AUTOSAR XML (schema 4-0-3)
standard types defined: Boolean, uint8, UInt16, UInt32, UInt8
package /AUTOSAR_Platform/DataConstrs
  range DC_Boolean: raw 0..1
  range DC_UInt16: raw 0..65535
  range DC_UInt8: raw 0..255
package /PATAC/Facility/DataTypes/Implementation
  compu method COMPU_Boolean: 0=FALSE, 1=TRUE
  unit NoUnit: factor-si-to-unit=1, offset-si-to-unit=0
package /PATAC/MSM/ComponentTypes
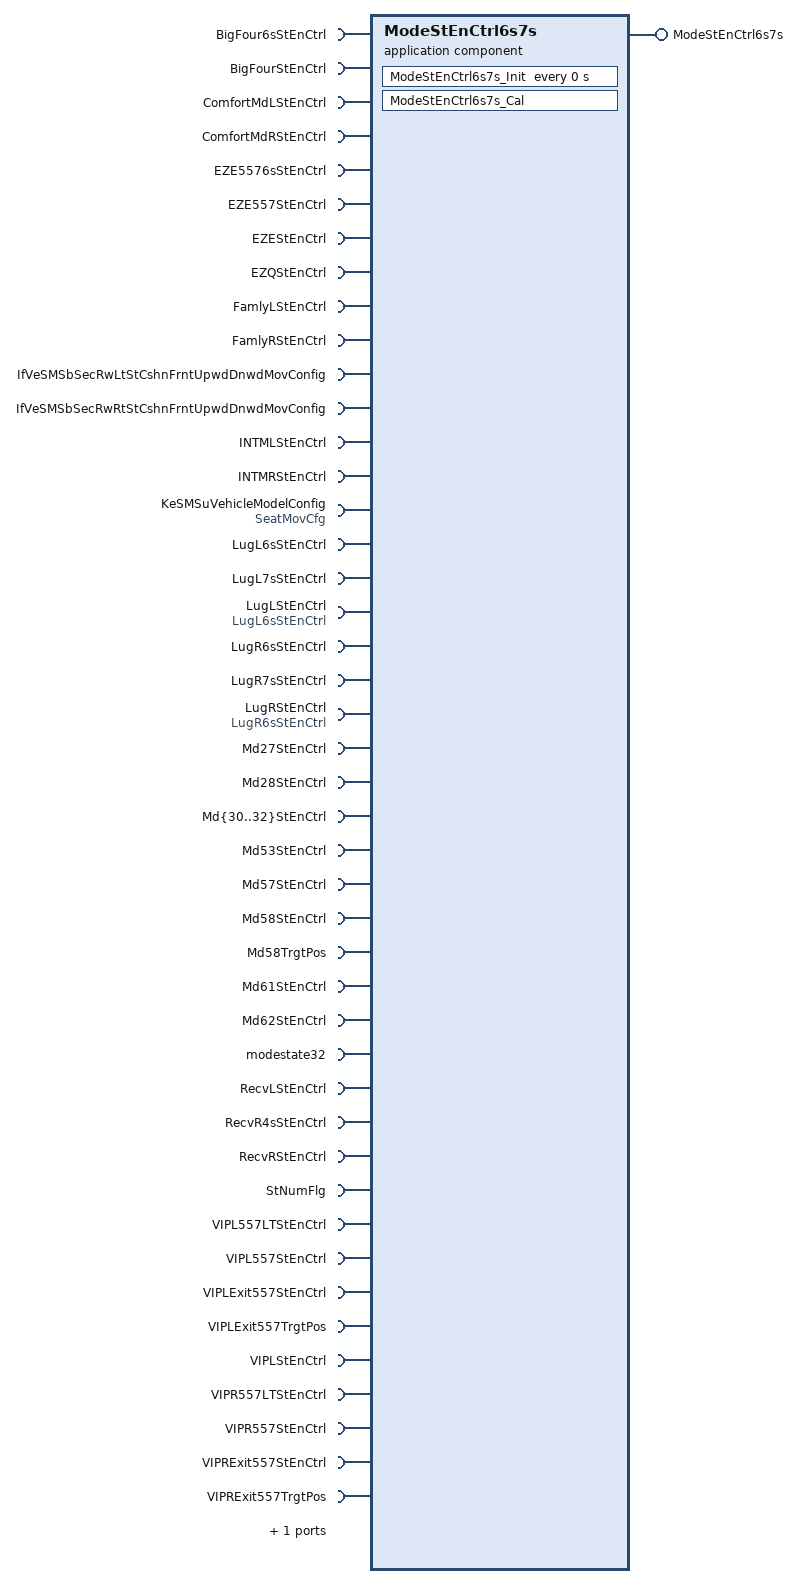
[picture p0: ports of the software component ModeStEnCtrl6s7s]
  application sw component type ModeStEnCtrl6s7s
    provide port ModeStEnCtrl6s7s: server-com-spec{operation=ModeStEnCtrl6s7s/Cal, queue-length=1}, provided-interface=ModeStEnCtrl6s7s
    47 x require port:
      BigFour6sStEnCtrl: client-com-spec=BigFour6sStEnCtrl/Cal, required-interface=BigFour6sStEnCtrl
      BigFourStEnCtrl: client-com-spec=BigFourStEnCtrl/Cal, required-interface=BigFourStEnCtrl
      ComfortMdLStEnCtrl: client-com-spec=ComfortMdLStEnCtrl/Cal, required-interface=ComfortMdLStEnCtrl
      ComfortMdRStEnCtrl: client-com-spec=ComfortMdRStEnCtrl/Cal, required-interface=ComfortMdRStEnCtrl
      EZE5576sStEnCtrl: client-com-spec=EZE5576sStEnCtrl/Cal, required-interface=EZE5576sStEnCtrl
      EZE557StEnCtrl: client-com-spec=EZE557StEnCtrl/Cal, required-interface=EZE557StEnCtrl
      EZEStEnCtrl: client-com-spec=EZEStEnCtrl/Cal, required-interface=EZEStEnCtrl
      EZQStEnCtrl: client-com-spec=EZQStEnCtrl/Cal, required-interface=EZQStEnCtrl
      FamlyLStEnCtrl: client-com-spec=FamlyLStEnCtrl/Cal, required-interface=FamlyLStEnCtrl
      FamlyRStEnCtrl: client-com-spec=FamlyRStEnCtrl/Cal, required-interface=FamlyRStEnCtrl
      IfVeSMSbSecRwLtStCshnFrntUpwdDnwdMovConfig: nonqueued-receiver-com-spec{data-element=IfVeSMSbSecRwLtStCshnFrntUpwdDnwdMovConfig/Val, filter=data-filter-type=ALWAYS, init-value=0}, required-interface=IfVeSMSbSecRwLtStCshnFrntUpwdDnwdMovConfig
      IfVeSMSbSecRwRtStCshnFrntUpwdDnwdMovConfig: nonqueued-receiver-com-spec{data-element=IfVeSMSbSecRwRtStCshnFrntUpwdDnwdMovConfig/Val, filter=data-filter-type=ALWAYS, init-value=0}, required-interface=IfVeSMSbSecRwRtStCshnFrntUpwdDnwdMovConfig
      INTMLStEnCtrl: client-com-spec=INTMLStEnCtrl/Cal, required-interface=INTMLStEnCtrl
      INTMRStEnCtrl: client-com-spec=INTMRStEnCtrl/Cal, required-interface=INTMRStEnCtrl
      KeSMSuVehicleModelConfig: parameter-require-com-spec{init-value=2, parameter=Val}, required-interface=SeatMovCfg
      LugL6sStEnCtrl: client-com-spec=LugL6sStEnCtrl/Cal, required-interface=LugL6sStEnCtrl
      LugL7sStEnCtrl: client-com-spec=LugL7sStEnCtrl/Cal, required-interface=LugL7sStEnCtrl
      LugLStEnCtrl: client-com-spec=LugL6sStEnCtrl/Cal, required-interface=LugL6sStEnCtrl
      LugR6sStEnCtrl: client-com-spec=LugR6sStEnCtrl/Cal, required-interface=LugR6sStEnCtrl
      LugR7sStEnCtrl: client-com-spec=LugR7sStEnCtrl/Cal, required-interface=LugR7sStEnCtrl
      LugRStEnCtrl: client-com-spec=LugR6sStEnCtrl/Cal, required-interface=LugR6sStEnCtrl
      Md27StEnCtrl: client-com-spec=Md27StEnCtrl/Cal, required-interface=Md27StEnCtrl
      Md28StEnCtrl: client-com-spec=Md28StEnCtrl/Cal, required-interface=Md28StEnCtrl
      Md{30..32}StEnCtrl: client-com-spec=Md{30..32}StEnCtrl/Cal, required-interface=Md{30..32}StEnCtrl
      Md53StEnCtrl: client-com-spec=Md53StEnCtrl/Cal, required-interface=Md53StEnCtrl
      Md57StEnCtrl: client-com-spec=Md57StEnCtrl/Cal, required-interface=Md57StEnCtrl
      Md58StEnCtrl: client-com-spec=Md58StEnCtrl/Cal, required-interface=Md58StEnCtrl
      Md58TrgtPos: required-com-specs=[Md58TrgtPos/Get, Md58TrgtPos/Set], required-interface=Md58TrgtPos
      Md61StEnCtrl: client-com-spec=Md61StEnCtrl/Cal, required-interface=Md61StEnCtrl
      Md62StEnCtrl: client-com-spec=Md62StEnCtrl/Cal, required-interface=Md62StEnCtrl
      modestate32: nonqueued-receiver-com-spec{data-element=modestate32/Val, filter=data-filter-type=ALWAYS, init-value=0}, required-interface=modestate32
      RecvLStEnCtrl: client-com-spec=RecvLStEnCtrl/Cal, required-interface=RecvLStEnCtrl
      RecvR4sStEnCtrl: client-com-spec=RecvR4sStEnCtrl/Cal, required-interface=RecvR4sStEnCtrl
      RecvRStEnCtrl: client-com-spec=RecvRStEnCtrl/Cal, required-interface=RecvRStEnCtrl
      StNumFlg: required-interface=StNumFlg
        required-com-specs:
          data-element=Is4s, filter=data-filter-type=ALWAYS, init-value=0
          data-element=Is6s, filter=data-filter-type=ALWAYS, init-value=0
          data-element=Is6s7s, filter=data-filter-type=ALWAYS, init-value=0
          data-element=Is7s, filter=data-filter-type=ALWAYS, init-value=0
      VIPL557LTStEnCtrl: client-com-spec=VIPL557LTStEnCtrl/Cal, required-interface=VIPL557LTStEnCtrl
      VIPL557StEnCtrl: client-com-spec=VIPL557StEnCtrl/Cal, required-interface=VIPL557StEnCtrl
      VIPLExit557StEnCtrl: client-com-spec=VIPLExit557StEnCtrl/Cal, required-interface=VIPLExit557StEnCtrl
      VIPLExit557TrgtPos: required-com-specs=[VIPLExit557TrgtPos/Get, VIPLExit557TrgtPos/Set], required-interface=VIPLExit557TrgtPos
      VIPLStEnCtrl: client-com-spec=VIPLStEnCtrl/Cal, required-interface=VIPLStEnCtrl
      VIPR557LTStEnCtrl: client-com-spec=VIPR557LTStEnCtrl/Cal, required-interface=VIPR557LTStEnCtrl
      VIPR557StEnCtrl: client-com-spec=VIPR557StEnCtrl/Cal, required-interface=VIPR557StEnCtrl
      VIPRExit557StEnCtrl: client-com-spec=VIPRExit557StEnCtrl/Cal, required-interface=VIPRExit557StEnCtrl
      VIPRExit557TrgtPos: required-com-specs=[VIPRExit557TrgtPos/Get, VIPRExit557TrgtPos/Set], required-interface=VIPRExit557TrgtPos
      VIPRStEnCtrl: client-com-spec=VIPRStEnCtrl/Cal, required-interface=VIPRStEnCtrl
    behavior ModeStEnCtrl6s7s_InternalBehavior
      operation invoked event OIT_ModeStEnCtrl6s7s_Cal_ModeStEnCtrl6s7s_Cal: start-on-event=ModeStEnCtrl6s7s_Cal, operation=ModeStEnCtrl6s7s.Cal
      timing event ModeStEnCtrl6s7s_InitEvent: start-on-event=ModeStEnCtrl6s7s_Init, period=0
      runnable ModeStEnCtrl6s7s_Cal
        data-receive-point-by-arguments:
          7 x access:
            REC_IfVeSMSbSecRwLtStCshnFrntUpwdDnwdMovConfig_Val: accessed-variable=IfVeSMSbSecRwLtStCshnFrntUpwdDnwdMovConfig.Val
            REC_IfVeSMSbSecRwRtStCshnFrntUpwdDnwdMovConfig_Val: accessed-variable=IfVeSMSbSecRwRtStCshnFrntUpwdDnwdMovConfig.Val
            REC_modestate32_Val: accessed-variable=modestate32.Val
            REC_StNumFlg_Is4s: accessed-variable=StNumFlg.Is4s
            REC_StNumFlg_Is6s: accessed-variable=StNumFlg.Is6s
            REC_StNumFlg_Is6s7s: accessed-variable=StNumFlg.Is6s7s
            REC_StNumFlg_Is7s: accessed-variable=StNumFlg.Is7s
        parameter access PA_KeSMSuVehicleModelConfig_Val: accessed-parameter=KeSMSuVehicleModelConfig.Val
        42 x sync call, all with timeout=0:
          SC_BigFour6sStEnCtrl_Cal: operation=BigFour6sStEnCtrl.Cal
          SC_BigFourStEnCtrl_Cal: operation=BigFourStEnCtrl.Cal
          SC_ComfortMdLStEnCtrl_Cal: operation=ComfortMdLStEnCtrl.Cal
          SC_ComfortMdRStEnCtrl_Cal: operation=ComfortMdRStEnCtrl.Cal
          SC_EZE5576sStEnCtrl_Cal: operation=EZE5576sStEnCtrl.Cal
          SC_EZE557StEnCtrl_Cal: operation=EZE557StEnCtrl.Cal
          SC_EZEStEnCtrl_Cal: operation=EZEStEnCtrl.Cal
          SC_EZQStEnCtrl_Cal: operation=EZQStEnCtrl.Cal
          SC_FamlyLStEnCtrl_Cal: operation=FamlyLStEnCtrl.Cal
          SC_FamlyRStEnCtrl_Cal: operation=FamlyRStEnCtrl.Cal
          SC_INTMLStEnCtrl_Cal: operation=INTMLStEnCtrl.Cal
          SC_INTMRStEnCtrl_Cal: operation=INTMRStEnCtrl.Cal
          SC_LugL6sStEnCtrl_Cal: operation=LugL6sStEnCtrl.Cal
          SC_LugL7sStEnCtrl_Cal: operation=LugL7sStEnCtrl.Cal
          SC_LugLStEnCtrl_Cal: operation=LugLStEnCtrl.Cal
          SC_LugR6sStEnCtrl_Cal: operation=LugR6sStEnCtrl.Cal
          SC_LugR7sStEnCtrl_Cal: operation=LugR7sStEnCtrl.Cal
          SC_LugRStEnCtrl_Cal: operation=LugRStEnCtrl.Cal
          SC_Md27StEnCtrl_Cal: operation=Md27StEnCtrl.Cal
          SC_Md28StEnCtrl_Cal: operation=Md28StEnCtrl.Cal
          SC_Md{30..32}StEnCtrl_Cal: operation=Md{30..32}StEnCtrl.Cal
          SC_Md53StEnCtrl_Cal: operation=Md53StEnCtrl.Cal
          SC_Md57StEnCtrl_Cal: operation=Md57StEnCtrl.Cal
          SC_Md58StEnCtrl_Cal: operation=Md58StEnCtrl.Cal
          SC_Md58TrgtPos_Set: operation=Md58TrgtPos.Set
          SC_Md61StEnCtrl_Cal: operation=Md61StEnCtrl.Cal
          SC_Md62StEnCtrl_Cal: operation=Md62StEnCtrl.Cal
          SC_RecvLStEnCtrl_Cal: operation=RecvLStEnCtrl.Cal
          SC_RecvR4sStEnCtrl_Cal: operation=RecvR4sStEnCtrl.Cal
          SC_RecvRStEnCtrl_Cal: operation=RecvRStEnCtrl.Cal
          SC_VIPL557LTStEnCtrl_Cal: operation=VIPL557LTStEnCtrl.Cal
          SC_VIPL557StEnCtrl_Cal: operation=VIPL557StEnCtrl.Cal
          SC_VIPLExit557StEnCtrl_Cal: operation=VIPLExit557StEnCtrl.Cal
          SC_VIPLExit557TrgtPos_Set: operation=VIPLExit557TrgtPos.Set
          SC_VIPLStEnCtrl_Cal: operation=VIPLStEnCtrl.Cal
          SC_VIPR557LTStEnCtrl_Cal: operation=VIPR557LTStEnCtrl.Cal
          SC_VIPR557StEnCtrl_Cal: operation=VIPR557StEnCtrl.Cal
          SC_VIPRExit557StEnCtrl_Cal: operation=VIPRExit557StEnCtrl.Cal
          SC_VIPRExit557TrgtPos_Set: operation=VIPRExit557TrgtPos.Set
          SC_VIPRStEnCtrl_Cal: operation=VIPRStEnCtrl.Cal
      runnable ModeStEnCtrl6s7s_Init
        parameter access PA_KeSMSuVehicleModelConfig_Val: accessed-parameter=KeSMSuVehicleModelConfig.Val
  swc implementation ModeStEnCtrl6s7s_Implementation: behavior=ModeStEnCtrl6s7s_InternalBehavior
    code-descriptors:
      code Default: artifact-descriptors=autosar-engineering-object={short-label=Default, category=SWSRC}
package /PATAC/MSM/DataTypes
  parameter interface SeatMovCfg
    parameter data prototype Val: sw-calibration-access=READ-WRITE, type=UInt8
package /PATAC/MSM/ModeAdjust/PortInterface
  41 x client server interface:
    BigFour6sStEnCtrl
      operation Cal
    BigFourStEnCtrl
      operation Cal
        arg FirstTrig: type=DataTypes/Boolean, direction=IN, server-argument-impl-policy=USE-ARGUMENT-TYPE
    ComfortMdLStEnCtrl
      operation Cal
    ComfortMdRStEnCtrl
      operation Cal
    EZE5576sStEnCtrl
      operation Cal
    EZE557StEnCtrl
      operation Cal
        arg FirstTrig: type=DataTypes/Boolean, direction=IN, server-argument-impl-policy=USE-ARGUMENT-TYPE
    EZEStEnCtrl
      operation Cal
    EZQStEnCtrl
      operation Cal
    FamlyLStEnCtrl
      operation Cal
    FamlyRStEnCtrl
      operation Cal
    INTMLStEnCtrl
      operation Cal
    INTMRStEnCtrl
      operation Cal
    LugL6sStEnCtrl
      operation Cal
    LugL7sStEnCtrl
      operation Cal
        arg FirstTrig: type=Implementation/Boolean, direction=IN, server-argument-impl-policy=USE-ARGUMENT-TYPE
    LugR6sStEnCtrl
      operation Cal
    LugR7sStEnCtrl
      operation Cal
        arg FirstTrig: type=Implementation/Boolean, direction=IN, server-argument-impl-policy=USE-ARGUMENT-TYPE
    Md27StEnCtrl
      operation Cal
    Md28StEnCtrl
      operation Cal
    Md30StEnCtrl
      operation Cal
        arg FirstTrig: type=Implementation/Boolean, direction=IN, server-argument-impl-policy=USE-ARGUMENT-TYPE
    Md31StEnCtrl
      operation Cal
        arg FirstTrig: type=Implementation/Boolean, direction=IN, server-argument-impl-policy=USE-ARGUMENT-TYPE
    Md32StEnCtrl
      operation Cal
        arg FirstTrig: type=Implementation/Boolean, direction=IN, server-argument-impl-policy=USE-ARGUMENT-TYPE
    Md53StEnCtrl
      operation Cal
        arg FirstTrig: type=Implementation/Boolean, direction=IN, server-argument-impl-policy=USE-ARGUMENT-TYPE
    Md57StEnCtrl
      operation Cal
        arg FirstTrig: type=DataTypes/Boolean, direction=IN, server-argument-impl-policy=USE-ARGUMENT-TYPE
    Md58StEnCtrl
      operation Cal
        arg FirstTrig: type=DataTypes/Boolean, direction=IN, server-argument-impl-policy=USE-ARGUMENT-TYPE
    Md58TrgtPos
      operation Get
        12 x arg, all with type=UInt16, direction=OUT, server-argument-impl-policy=USE-ARGUMENT-TYPE:
          SecRwRtStBkReclnTrgtPos
          SecRwRtStZeroTrgtPos
          SecRwRtStLgrstUpwdDnwdTrgtPos
          SecRwRtStLgrstInwdOtwdTrgtPos
          ThdRwLtStBkReclnTrgtPos
          ThdRwLtStFwdBkwdTrgtPos
          ThdRwRtStBkReclnTrgtPos
          ThdRwRtStFwdBkwdTrgtPos
          PassStBkReclnTrgtPos
          PassStFwdBkwdTrgtPos
          SecRwRtStFwdBkwdTrgtPos
          PassStFldTrgtPos
      operation Set
    Md61StEnCtrl
      operation Cal
        arg FirstTrig: type=Implementation/Boolean, direction=IN, server-argument-impl-policy=USE-ARGUMENT-TYPE
    Md62StEnCtrl
      operation Cal
        arg FirstTrig: type=Implementation/Boolean, direction=IN, server-argument-impl-policy=USE-ARGUMENT-TYPE
    ModeStEnCtrl6s7s
      operation Cal
    RecvLStEnCtrl
      operation Cal
    RecvR4sStEnCtrl
      operation Cal
    RecvRStEnCtrl
      operation Cal
    VIPL557LTStEnCtrl
      operation Cal
    VIPL557StEnCtrl
      operation Cal
        arg FirstTrig: type=DataTypes/Boolean, direction=IN, server-argument-impl-policy=USE-ARGUMENT-TYPE
    VIPLExit557StEnCtrl
      operation Cal
        arg FirstTrig: type=DataTypes/Boolean, direction=IN, server-argument-impl-policy=USE-ARGUMENT-TYPE
    VIPLExit557TrgtPos
      operation Get
        7 x arg, all with type=UInt16, direction=OUT, server-argument-impl-policy=USE-ARGUMENT-TYPE:
          SecRwLtStBkReclnTrgtPos
          SecRwLtStZeroTrgtPos
          SecRwLtStLgrstUpwdDnwdTrgtPos
          SecRwLtStLgrstInwdOtwdTrgtPos
          ThdRwLtStBkReclnTrgtPos
          ThdRwLtStFwdBkwdTrgtPos
          SecRwLtStFwdBkwdTrgtPos
      operation Set
    VIPLStEnCtrl
      operation Cal
    VIPR557LTStEnCtrl
      operation Cal
    VIPR557StEnCtrl
      operation Cal
        arg FirstTrig: type=DataTypes/Boolean, direction=IN, server-argument-impl-policy=USE-ARGUMENT-TYPE
    VIPRExit557StEnCtrl
      operation Cal
        arg FirstTrig: type=DataTypes/Boolean, direction=IN, server-argument-impl-policy=USE-ARGUMENT-TYPE
    VIPRExit557TrgtPos
      operation Get
        11 x arg, all with type=UInt16, direction=OUT, server-argument-impl-policy=USE-ARGUMENT-TYPE:
          SecRwRtStBkReclnTrgtPos
          SecRwRtStZeroTrgtPos
          SecRwRtStLgrstUpwdDnwdTrgtPos
          SecRwRtStLgrstInwdOtwdTrgtPos
          ThdRwLtStBkReclnTrgtPos
          ThdRwLtStFwdBkwdTrgtPos
          ThdRwRtStBkReclnTrgtPos
          ThdRwRtStFwdBkwdTrgtPos
          PassStBkReclnTrgtPos
          PassStFwdBkwdTrgtPos
          SecRwRtStFwdBkwdTrgtPos
      operation Set
    VIPRStEnCtrl
      operation Cal
  sender receiver interface modestate32: invalidation-policy{data-element=modestate32/Val, handle-invalid=DONT-INVALIDATE}
    data Val: type=UInt32
  sender receiver interface StNumFlg
    4 x data, all with type=Implementation/Boolean:
      Is4s
      Is6s
      Is6s7s
      Is7s
    invalidation-policys:
      data-element=Is4s, handle-invalid=DONT-INVALIDATE
      data-element=Is6s, handle-invalid=DONT-INVALIDATE
      data-element=Is6s7s, handle-invalid=DONT-INVALIDATE
      data-element=Is7s, handle-invalid=DONT-INVALIDATE
package /PATAC/MSM/PortInterfaces
  sender receiver interface IfVeSMSbSecRwLtStCshnFrntUpwdDnwdMovConfig: invalidation-policy{data-element=IfVeSMSbSecRwLtStCshnFrntUpwdDnwdMovConfig/Val, handle-invalid=DONT-INVALIDATE}
    data Val: type=Implementation/Boolean
  sender receiver interface IfVeSMSbSecRwRtStCshnFrntUpwdDnwdMovConfig: invalidation-policy{data-element=IfVeSMSbSecRwRtStCshnFrntUpwdDnwdMovConfig/Val, handle-invalid=DONT-INVALIDATE}
    data Val: type=Implementation/Boolean
